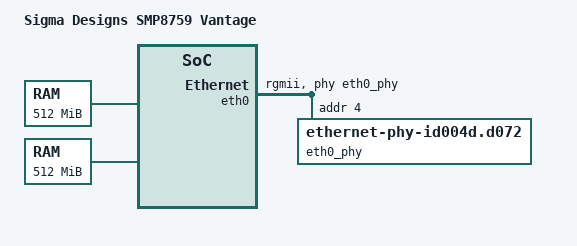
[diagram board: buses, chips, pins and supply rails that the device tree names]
/dts-v1/;

#include "smp87xx.dtsi"

/ {
	compatible = "sigma,smp8759-vantage", "sigma,smp8759-soc";
	model = "Sigma Designs SMP8759 Vantage";

	aliases {
		serial0 = &uart0;
	};

	memory@80000000 {
		device_type = "memory";
		reg = <0x80000000 0x20000000>;
	};

	memory@c0000000 {
		device_type = "memory";
		reg = <0xc0000000 0x20000000>;
	};

	chosen {
		stdout-path = "serial0:115200n8";
	};
};

&eth0 {
	phy-connection-type = "rgmii";
	phy-handle = <&eth0_phy>;

	eth0_phy: ethernet-phy@4 {
		compatible = "ethernet-phy-id004d.d072",
			     "ethernet-phy-ieee802.3-c22";
		reg = <4>;
		interrupts = <37 IRQ_TYPE_EDGE_RISING>;
	};
};

&sata_phy {
	clock-frequency = <60>;
	sigma,internal-clock;
	sigma,rx-ssc = <1 1>;
	sigma,tx-ssc = <1>;
	sigma,tx-erc = <5>;
};
